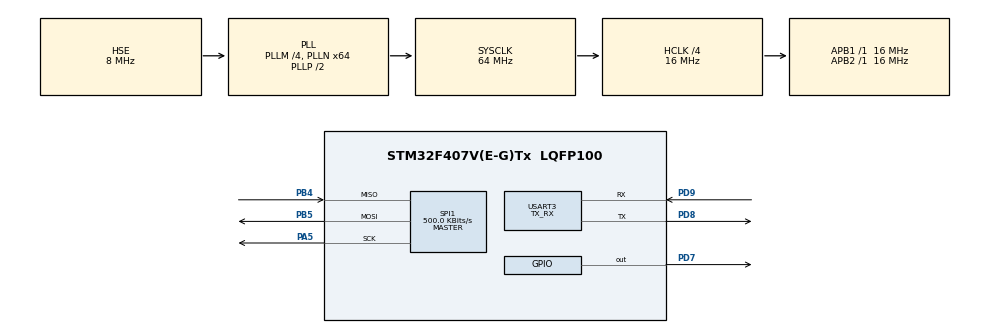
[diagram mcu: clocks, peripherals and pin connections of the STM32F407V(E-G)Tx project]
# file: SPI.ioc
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Mcu.Family=STM32F4
Mcu.Name=STM32F407V(E-G)Tx
Mcu.Package=LQFP100
NVIC.PriorityGroup=NVIC_PRIORITYGROUP_4
NVIC.USART3_IRQn=true\:0\:0\:false\:false\:true\:true\:true
PA5.Mode=Full_Duplex_Master
PA5.Signal=SPI1_SCK
PB4.Mode=Full_Duplex_Master
PB4.Signal=SPI1_MISO
PB5.Mode=Full_Duplex_Master
PB5.Signal=SPI1_MOSI
PD7.GPIO_PuPd=GPIO_PULLUP
PD7.GPIO_Speed=GPIO_SPEED_FREQ_VERY_HIGH
PD7.Signal=GPIO_Output
PD8.Mode=Asynchronous
PD8.Signal=USART3_TX
PD9.Mode=Asynchronous
PD9.Signal=USART3_RX
PH0-OSC_IN.Mode=HSE-External-Oscillator
PH0-OSC_IN.Signal=RCC_OSC_IN
PH1-OSC_OUT.Mode=HSE-External-Oscillator
PH1-OSC_OUT.Signal=RCC_OSC_OUT
ProjectManager.HeapSize=0x200
ProjectManager.StackSize=0x400
ProjectManager.TargetToolchain=STM32CubeIDE
RCC.48MHZClocksFreq_Value=32000000
RCC.AHBCLKDivider=RCC_SYSCLK_DIV4
RCC.AHBFreq_Value=16000000
RCC.APB1Freq_Value=16000000
RCC.APB1TimFreq_Value=16000000
RCC.APB2Freq_Value=16000000
RCC.APB2TimFreq_Value=16000000
RCC.CortexFreq_Value=16000000
RCC.HCLKFreq_Value=16000000
RCC.HSE_VALUE=8000000
RCC.HSI_VALUE=16000000
RCC.LSE_VALUE=32768
RCC.PLLM=4
RCC.PLLN=64
RCC.PLLSourceVirtual=RCC_PLLSOURCE_HSE
RCC.SYSCLKFreq_VALUE=64000000
RCC.SYSCLKSource=RCC_SYSCLKSOURCE_PLLCLK
RCC.VCOOutputFreq_Value=128000000
SPI1.BaudRatePrescaler=SPI_BAUDRATEPRESCALER_32
SPI1.CLKPhase=SPI_PHASE_1EDGE
SPI1.CLKPolarity=SPI_POLARITY_LOW
SPI1.CalculateBaudRate=500.0 KBits/s
SPI1.Direction=SPI_DIRECTION_2LINES
SPI1.Mode=SPI_MODE_MASTER
SPI1.VirtualType=VM_MASTER
USART3.Mode=MODE_TX_RX
USART3.Parity=PARITY_NONE
USART3.StopBits=STOPBITS_1
USART3.VirtualMode=VM_ASYNC
USART3.WordLength=WORDLENGTH_8B
board=custom

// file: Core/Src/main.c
/* USER CODE BEGIN Header */
/**
  ******************************************************************************
  * @file           : main.c
  * @brief          : Main program body
  ******************************************************************************
  * @attention
  *
  * <h2><center>&copy; Copyright (c) 2021 STMicroelectronics.
  * All rights reserved.</center></h2>
  *
  * This software component is licensed by ST under BSD 3-Clause license,
  * the "License"; You may not use this file except in compliance with the
  * License. You may obtain a copy of the License at:
  *                        opensource.org/licenses/BSD-3-Clause
  *
  ******************************************************************************
  */
/* USER CODE END Header */
#include "main.h"
#include "spi.h"
#include "usart.h"
#include "gpio.h"

/* USER CODE BEGIN Includes */
#include "spi_driver.h"
/* USER CODE END Includes */

void SystemClock_Config(void);

int main(void)
{

  /* MCU Configuration--------------------------------------------------------*/

  /* Reset of all peripherals, Initializes the Flash interface and the Systick. */
  HAL_Init();

  /* Configure the system clock */
  SystemClock_Config();

  /* Initialize all configured peripherals */
  MX_GPIO_Init();
  MX_SPI1_Init();
  MX_USART3_UART_Init();
  /* USER CODE BEGIN 2 */
  HOME_SCREEN();
  /* USER CODE END 2 */

  /* Infinite loop */
  while (1)
  {

  }
}

void SystemClock_Config(void)
{
  RCC_OscInitTypeDef RCC_OscInitStruct = {0};
  RCC_ClkInitTypeDef RCC_ClkInitStruct = {0};

  /** Configure the main internal regulator output voltage
  */
  __HAL_RCC_PWR_CLK_ENABLE();
  __HAL_PWR_VOLTAGESCALING_CONFIG(PWR_REGULATOR_VOLTAGE_SCALE1);
  /** Initializes the RCC Oscillators according to the specified parameters
  * in the RCC_OscInitTypeDef structure.
  */
  RCC_OscInitStruct.OscillatorType = RCC_OSCILLATORTYPE_HSE;
  RCC_OscInitStruct.HSEState = RCC_HSE_ON;
  RCC_OscInitStruct.PLL.PLLState = RCC_PLL_ON;
  RCC_OscInitStruct.PLL.PLLSource = RCC_PLLSOURCE_HSE;
  RCC_OscInitStruct.PLL.PLLM = 4;
  RCC_OscInitStruct.PLL.PLLN = 64;
  RCC_OscInitStruct.PLL.PLLP = RCC_PLLP_DIV2;
  RCC_OscInitStruct.PLL.PLLQ = 4;
  if (HAL_RCC_OscConfig(&RCC_OscInitStruct) != HAL_OK)
  {
    Error_Handler();
  }
  /** Initializes the CPU, AHB and APB buses clocks
  */
  RCC_ClkInitStruct.ClockType = RCC_CLOCKTYPE_HCLK|RCC_CLOCKTYPE_SYSCLK
                              |RCC_CLOCKTYPE_PCLK1|RCC_CLOCKTYPE_PCLK2;
  RCC_ClkInitStruct.SYSCLKSource = RCC_SYSCLKSOURCE_PLLCLK;
  RCC_ClkInitStruct.AHBCLKDivider = RCC_SYSCLK_DIV4;
  RCC_ClkInitStruct.APB1CLKDivider = RCC_HCLK_DIV1;
  RCC_ClkInitStruct.APB2CLKDivider = RCC_HCLK_DIV1;

  if (HAL_RCC_ClockConfig(&RCC_ClkInitStruct, FLASH_LATENCY_0) != HAL_OK)
  {
    Error_Handler();
  }
}

void Error_Handler(void)
{
  __disable_irq();
  while (1)
  {
  }
}

/************************ (C) COPYRIGHT STMicroelectronics *****END OF FILE****/
